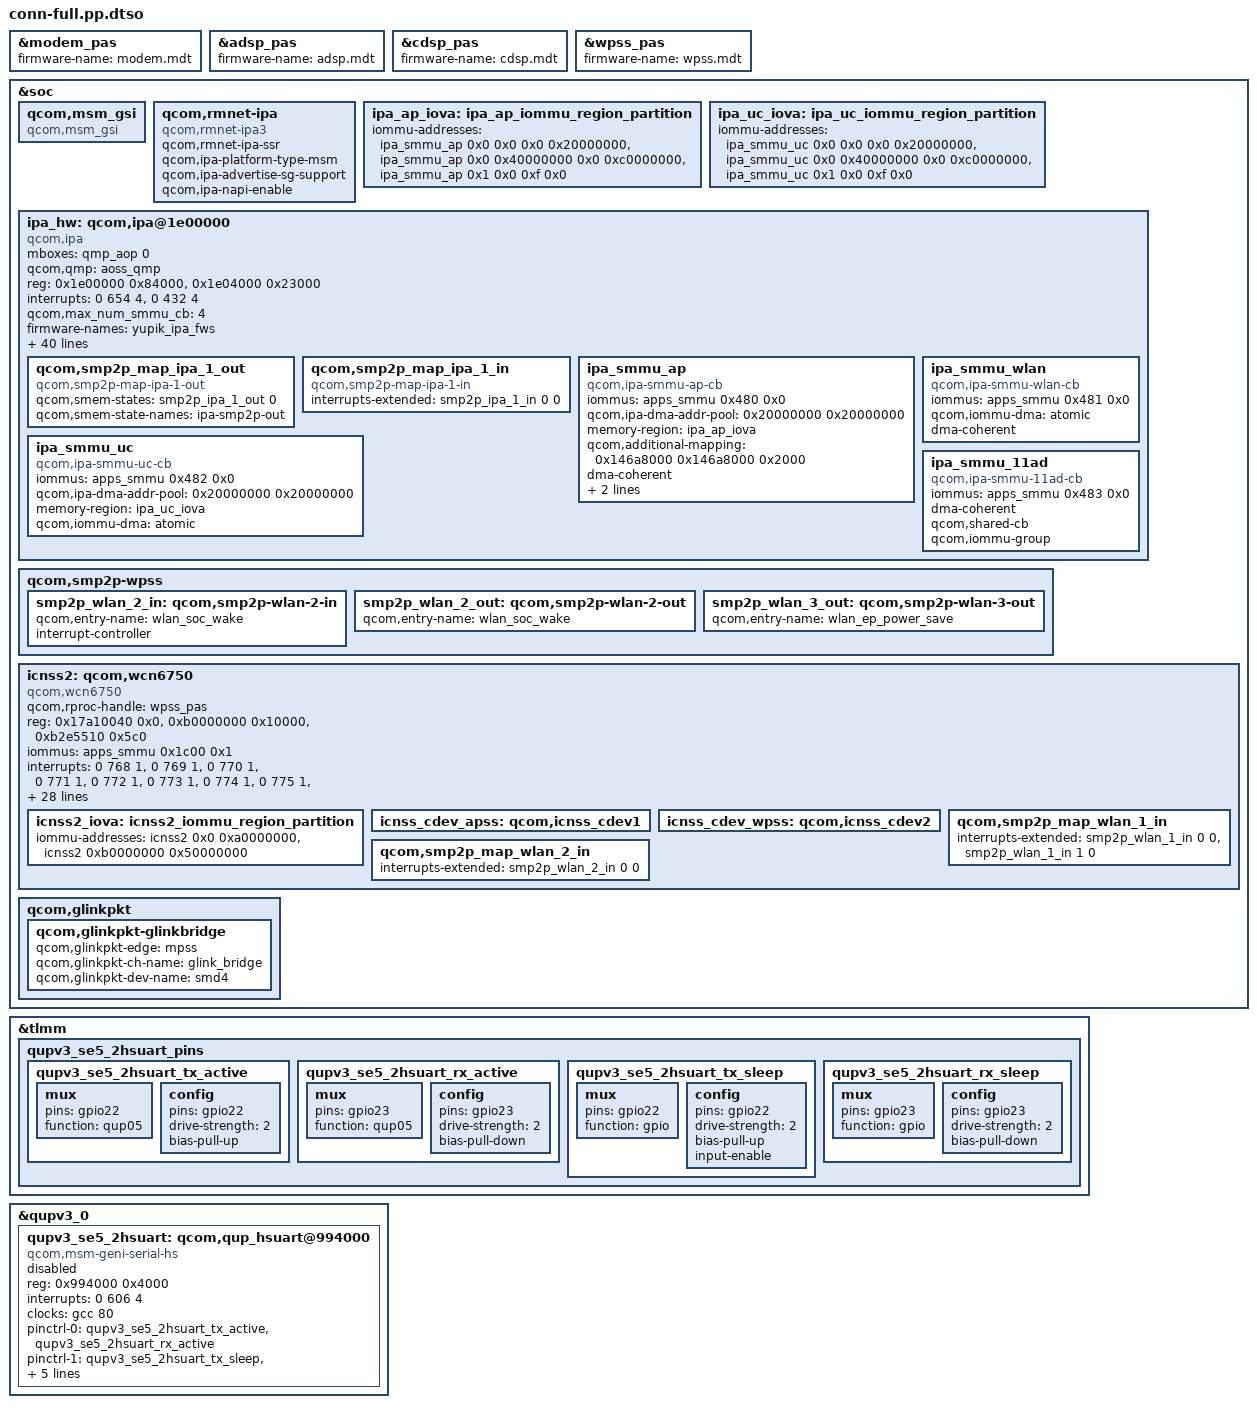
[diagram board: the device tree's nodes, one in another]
/dts-v1/; /plugin/;
&modem_pas {
 firmware-name = "modem.mdt";
 status = "ok";
};
&adsp_pas {
 firmware-name = "adsp.mdt";
};
&cdsp_pas {
 firmware-name = "cdsp.mdt";
};
&wpss_pas {
 firmware-name = "wpss.mdt";
};
&soc {
 qcom,msm_gsi {
  compatible = "qcom,msm_gsi";
 };
 qcom,rmnet-ipa {
  compatible = "qcom,rmnet-ipa3";
  qcom,rmnet-ipa-ssr;
  qcom,ipa-platform-type-msm;
  qcom,ipa-advertise-sg-support;
  qcom,ipa-napi-enable;
 };
 ipa_ap_iova: ipa_ap_iommu_region_partition {
  iommu-addresses = <&ipa_smmu_ap 0x0 0x0 0x0 0x20000000>,
      <&ipa_smmu_ap 0x0 0x40000000 0x0 0xc0000000>,
      <&ipa_smmu_ap 0x1 0x0 0xf 0x0>;
 };
 ipa_uc_iova: ipa_uc_iommu_region_partition {
  iommu-addresses = <&ipa_smmu_uc 0x0 0x0 0x0 0x20000000>,
      <&ipa_smmu_uc 0x0 0x40000000 0x0 0xc0000000>,
      <&ipa_smmu_uc 0x1 0x0 0xf 0x0>;
 };
 ipa_hw: qcom,ipa@1e00000 {
  compatible = "qcom,ipa";
  mboxes = <&qmp_aop 0>;
  qcom,qmp = <&aoss_qmp>;
  reg = <0x1e00000 0x84000>, <0x1e04000 0x23000>;
  reg-names = "ipa-base", "gsi-base";
  interrupts = <0 654 4>,
        <0 432 4>;
  interrupt-names = "ipa-irq", "gsi-irq";
  qcom,max_num_smmu_cb = <4>;
  firmware-names = "yupik_ipa_fws";
  pas-ids = <0xf>;
  memory-regions = <&pil_ipa_gsi_mem>;
  qcom,ipa-hw-ver = <20>;
  qcom,ipa-hw-mode = <0>;
  qcom,platform-type = <1>;
  qcom,ee = <0>;
  qcom,use-ipa-tethering-bridge;
  qcom,modem-cfg-emb-pipe-flt;
  qcom,ipa-wdi3-over-gsi;
  qcom,arm-smmu;
  qcom,smmu-fast-map;
  qcom,use-64-bit-dma-mask;
  qcom,ipa-endp-delay-wa-v2;
  qcom,eth-bridging-not-supported;
  qcom,bw-monitor-supported;
  qcom,lan-rx-napi;
  qcom,tx-napi;
  qcom,wan-use-skb-page;
  qcom,rmnet-ctl-enable;
  qcom,use-gsi-ipa-fw = "yupik_ipa_fws";
  qcom,tx-wrapper-cache-max-size = <400>;
  qcom,ipa-gpi-event-rp-ddr;
  clock-names = "core_clk";
  clocks = <&rpmhcc 12>;
  qcom,interconnect,num-cases = <5>;
  qcom,interconnect,num-paths = <3>;
  interconnects = <&aggre2_noc 38 &gem_noc 573>,
    <&mc_virt 3 &mc_virt 512>,
    <&gem_noc 2 &cnoc2 529>;
  interconnect-names = "ipa_to_llcc", "llcc_to_ebi1", "appss_to_ipa";
  qcom,no-vote = <0 0 0 0 0 0>;
  qcom,svs2 = <150000 600000 150000 1804000 0 74000>;
  qcom,svs = <625000 1200000 625000 3072000 0 150000>;
  qcom,nominal = <1250000 2400000 1250000 6220800 0 400000>;
  qcom,turbo = <2000000 3500000 2000000 7219200 0 400000>;
  qcom,bus-vector-names = "MIN", "SVS2", "SVS", "NOMINAL", "TURBO";
  qcom,throughput-threshold = <600 2500 5000>;
  qcom,scaling-exceptions = <>;
  qcom,smp2p_map_ipa_1_out {
   compatible = "qcom,smp2p-map-ipa-1-out";
   qcom,smem-states = <&smp2p_ipa_1_out 0>;
   qcom,smem-state-names = "ipa-smp2p-out";
  };
  qcom,smp2p_map_ipa_1_in {
   compatible = "qcom,smp2p-map-ipa-1-in";
   interrupts-extended = <&smp2p_ipa_1_in 0 0>;
   interrupt-names = "ipa-smp2p-in";
  };
  ipa_smmu_ap: ipa_smmu_ap {
   compatible = "qcom,ipa-smmu-ap-cb";
   iommus = <&apps_smmu 0x480 0x0>;
   qcom,ipa-dma-addr-pool = <0x20000000 0x20000000>;
   memory-region = <&ipa_ap_iova>;
   qcom,additional-mapping = <0x146a8000 0x146a8000 0x2000>;
   dma-coherent;
   qcom,iommu-dma = "fastmap";
   qcom,ipa-q6-smem-size = <36864>;
  };
  ipa_smmu_wlan: ipa_smmu_wlan {
   compatible = "qcom,ipa-smmu-wlan-cb";
   iommus = <&apps_smmu 0x481 0x0>;
   qcom,iommu-dma = "atomic";
   dma-coherent;
  };
  ipa_smmu_uc: ipa_smmu_uc {
   compatible = "qcom,ipa-smmu-uc-cb";
   iommus = <&apps_smmu 0x482 0x0>;
   qcom,ipa-dma-addr-pool = <0x20000000 0x20000000>;
   memory-region = <&ipa_uc_iova>;
   qcom,iommu-dma = "atomic";
  };
  ipa_smmu_11ad: ipa_smmu_11ad {
   compatible = "qcom,ipa-smmu-11ad-cb";
   iommus = <&apps_smmu 0x483 0x0>;
   dma-coherent;
   qcom,shared-cb;
   qcom,iommu-group;
  };
 };
};
&soc {
 qcom,smp2p-wpss {
  smp2p_wlan_2_in: qcom,smp2p-wlan-2-in {
   qcom,entry-name = "wlan_soc_wake";
   interrupt-controller;
   #interrupt-cells = <2>;
  };
  smp2p_wlan_2_out: qcom,smp2p-wlan-2-out {
   qcom,entry-name = "wlan_soc_wake";
   #qcom,smem-state-cells = <1>;
  };
  smp2p_wlan_3_out: qcom,smp2p-wlan-3-out {
   qcom,entry-name = "wlan_ep_power_save";
   #qcom,smem-state-cells = <1>;
  };
 };
 icnss2: qcom,wcn6750 {
  compatible = "qcom,wcn6750";
  qcom,rproc-handle = <&wpss_pas>;
  reg = <0x17a10040 0x0>,
        <0xb0000000 0x10000>,
        <0xb2e5510 0x5c0>;
  reg-names = "msi_addr", "smmu_iova_ipa", "tcs_cmd";
  iommus = <&apps_smmu 0x1c00 0x1>;
  interrupts = <0 768 1>,
        <0 769 1>,
        <0 770 1>,
        <0 771 1>,
        <0 772 1>,
        <0 773 1>,
        <0 774 1>,
        <0 775 1>,
        <0 776 1>,
        <0 777 1>,
        <0 778 1>,
        <0 779 1>,
        <0 780 1>,
        <0 781 1>,
        <0 782 1>,
        <0 783 1>,
        <0 784 1>,
        <0 785 1>,
        <0 786 1>,
        <0 787 1>,
        <0 788 1>,
        <0 789 1>,
        <0 790 1>,
        <0 791 1>,
        <0 792 1>,
        <0 793 1>,
        <0 794 1>,
        <0 795 1>,
        <0 796 1>,
        <0 797 1>,
        <0 798 1>,
        <0 799 1>;
  qcom,iommu-dma = "fastmap";
  qcom,iommu-faults = "stall-disable", "HUPCF", "non-fatal";
  memory-region = <&icnss2_iova>;
  qcom,iommu-geometry = <0xa0000000 0x10010000>;
  qcom,wlan-msa-fixed-region = <&wlan_fw_mem>;
  qcom,cmd_db_name = "smpb7";
  cnss-daemon-support;
  dma-coherent;
  qcom,fw-prefix;
  vdd-cx-mx-supply = <&S7B>;
  qcom,vdd-cx-mx-config = <824000 1120000 0 0 1>;
  vdd-1.8-xo-supply = <&S1B>;
  qcom,vdd-1.8-xo-config = <1872000 2040000 0 0 0>;
  vdd-1.3-rfa-supply = <&S8B>;
  qcom,vdd-1.3-rfa-config = <1256000 1500000 0 0 0>;
  qcom,smem-states = <&smp2p_wlan_1_out 0>,
       <&smp2p_wlan_2_out 0>,
       <&smp2p_wlan_3_out 0>;
  qcom,smem-state-names = "wlan-smp2p-out",
     "wlan-soc-wake-smp2p-out",
     "wlan-ep-powersave-smp2p-out";
  icnss2_iova: icnss2_iommu_region_partition {
   iommu-addresses = <&icnss2 0x0 0xa0000000>,
       <&icnss2 0xb0000000 0x50000000>;
  };
  icnss_cdev_apss: qcom,icnss_cdev1 {
   #cooling-cells = <2>;
  };
  icnss_cdev_wpss: qcom,icnss_cdev2 {
   #cooling-cells = <2>;
  };
  qcom,smp2p_map_wlan_1_in {
   interrupts-extended = <&smp2p_wlan_1_in 0 0>,
           <&smp2p_wlan_1_in 1 0>;
   interrupt-names = "qcom,smp2p-force-fatal-error",
       "qcom,smp2p-early-crash-ind";
  };
  qcom,smp2p_map_wlan_2_in {
   interrupts-extended = <&smp2p_wlan_2_in 0 0>;
   interrupt-names = "qcom,smp2p-soc-wake-ack";
  };
 };
};
&wpss_pas {
 firmware-name = "wpss.mdt";
};
&icnss2 {
 qcom,wlan;
 qcom,wlan-legacy-ipc-transport;
};
&soc {
 qcom,glinkpkt {
  qcom,glinkpkt-glinkbridge {
   qcom,glinkpkt-edge = "mpss";
   qcom,glinkpkt-ch-name = "glink_bridge";
   qcom,glinkpkt-dev-name = "smd4";
  };
 };
};
&tlmm {
 qupv3_se5_2hsuart_pins: qupv3_se5_2hsuart_pins {
  qupv3_se5_2hsuart_tx_active: qupv3_se5_2hsuart_tx_active {
   mux {
    pins = "gpio22";
    function = "qup05";
   };
   config {
    pins = "gpio22";
    drive-strength = <2>;
    bias-pull-up;
   };
  };
  qupv3_se5_2hsuart_rx_active: qupv3_se5_2hsuart_rx_active {
   mux {
    pins = "gpio23";
    function = "qup05";
   };
   config {
    pins = "gpio23";
    drive-strength = <2>;
    bias-pull-down;
   };
  };
  qupv3_se5_2hsuart_tx_sleep: qupv3_se5_2hsuart_tx_sleep {
   mux {
    pins = "gpio22";
    function = "gpio";
   };
   config {
    pins = "gpio22";
    drive-strength = <2>;
    bias-pull-up;
    input-enable;
   };
  };
  qupv3_se5_2hsuart_rx_sleep: qupv3_se5_2hsuart_rx_sleep {
   mux {
    pins = "gpio23";
    function = "gpio";
   };
   config {
    pins = "gpio23";
    drive-strength = <2>;
    bias-pull-down;
   };
  };
 };
};
&qupv3_0 {
 qupv3_se5_2hsuart: qcom,qup_hsuart@994000 {
  compatible = "qcom,msm-geni-serial-hs";
  reg = <0x994000 0x4000>;
  reg-names = "se_phys";
  interrupts = <0 606 4>;
  clock-names = "se-clk";
  clocks = <&gcc 80>;
  pinctrl-names = "default", "sleep";
  pinctrl-0 = <&qupv3_se5_2hsuart_tx_active>,
       <&qupv3_se5_2hsuart_rx_active>;
  pinctrl-1 = <&qupv3_se5_2hsuart_tx_sleep>,
       <&qupv3_se5_2hsuart_rx_sleep>;
  interconnect-names = "qup-core", "qup-config", "qup-memory";
  interconnects = <&clk_virt 32 &clk_virt 581>,
    <&gem_noc 2 &cnoc2 549>,
    <&aggre1_noc 8 &mc_virt 512>;
  always-on-clock;
  status = "disabled";
 };
};
